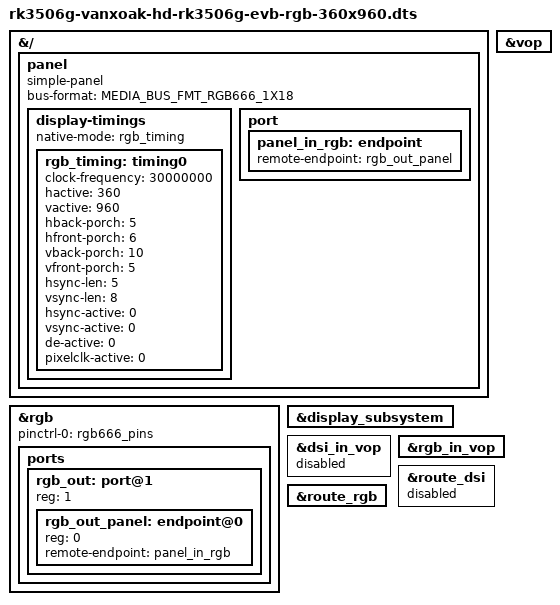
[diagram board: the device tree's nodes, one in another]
// SPDX-License-Identifier: (GPL-2.0+ OR MIT)
/*
 * Copyright (c) 2024 Rockchip Electronics Co., Ltd.
 */

/dts-v1/;
/plugin/;

#include <dt-bindings/display/media-bus-format.h>

&{/} {
	panel: panel {
		compatible = "simple-panel";
		bus-format = <MEDIA_BUS_FMT_RGB666_1X18>;
		status = "okay";

		display-timings {
			native-mode = <&rgb_timing>;

			rgb_timing: timing0 {
				clock-frequency = <30000000>;
				hactive = <360>;
				vactive = <960>;
				hback-porch = <5>;
				hfront-porch = <6>;
				vback-porch = <10>;
				vfront-porch = <5>;
				hsync-len = <5>;
				vsync-len = <8>;
				hsync-active = <0>;
				vsync-active = <0>;
				de-active = <0>;
				pixelclk-active = <0>;
			};
		};

		port {
			panel_in_rgb: endpoint {
				remote-endpoint = <&rgb_out_panel>;
			};
		};
	};
};

&rgb {
	status = "okay";
	pinctrl-names = "default";
	pinctrl-0 = <&rgb666_pins>;

	ports {
		rgb_out: port@1 {
			reg = <1>;
			#address-cells = <1>;
			#size-cells = <0>;

			rgb_out_panel: endpoint@0 {
				reg = <0>;
				remote-endpoint = <&panel_in_rgb>;
			};
		};
	};
};

&display_subsystem {
	status = "okay";
};

&vop {
	status = "okay";
};

&dsi_in_vop {
	status = "disabled";
};

&rgb_in_vop {
	status = "okay";
};

&route_dsi {
	status = "disabled";
};

&route_rgb {
	status = "okay";
};
